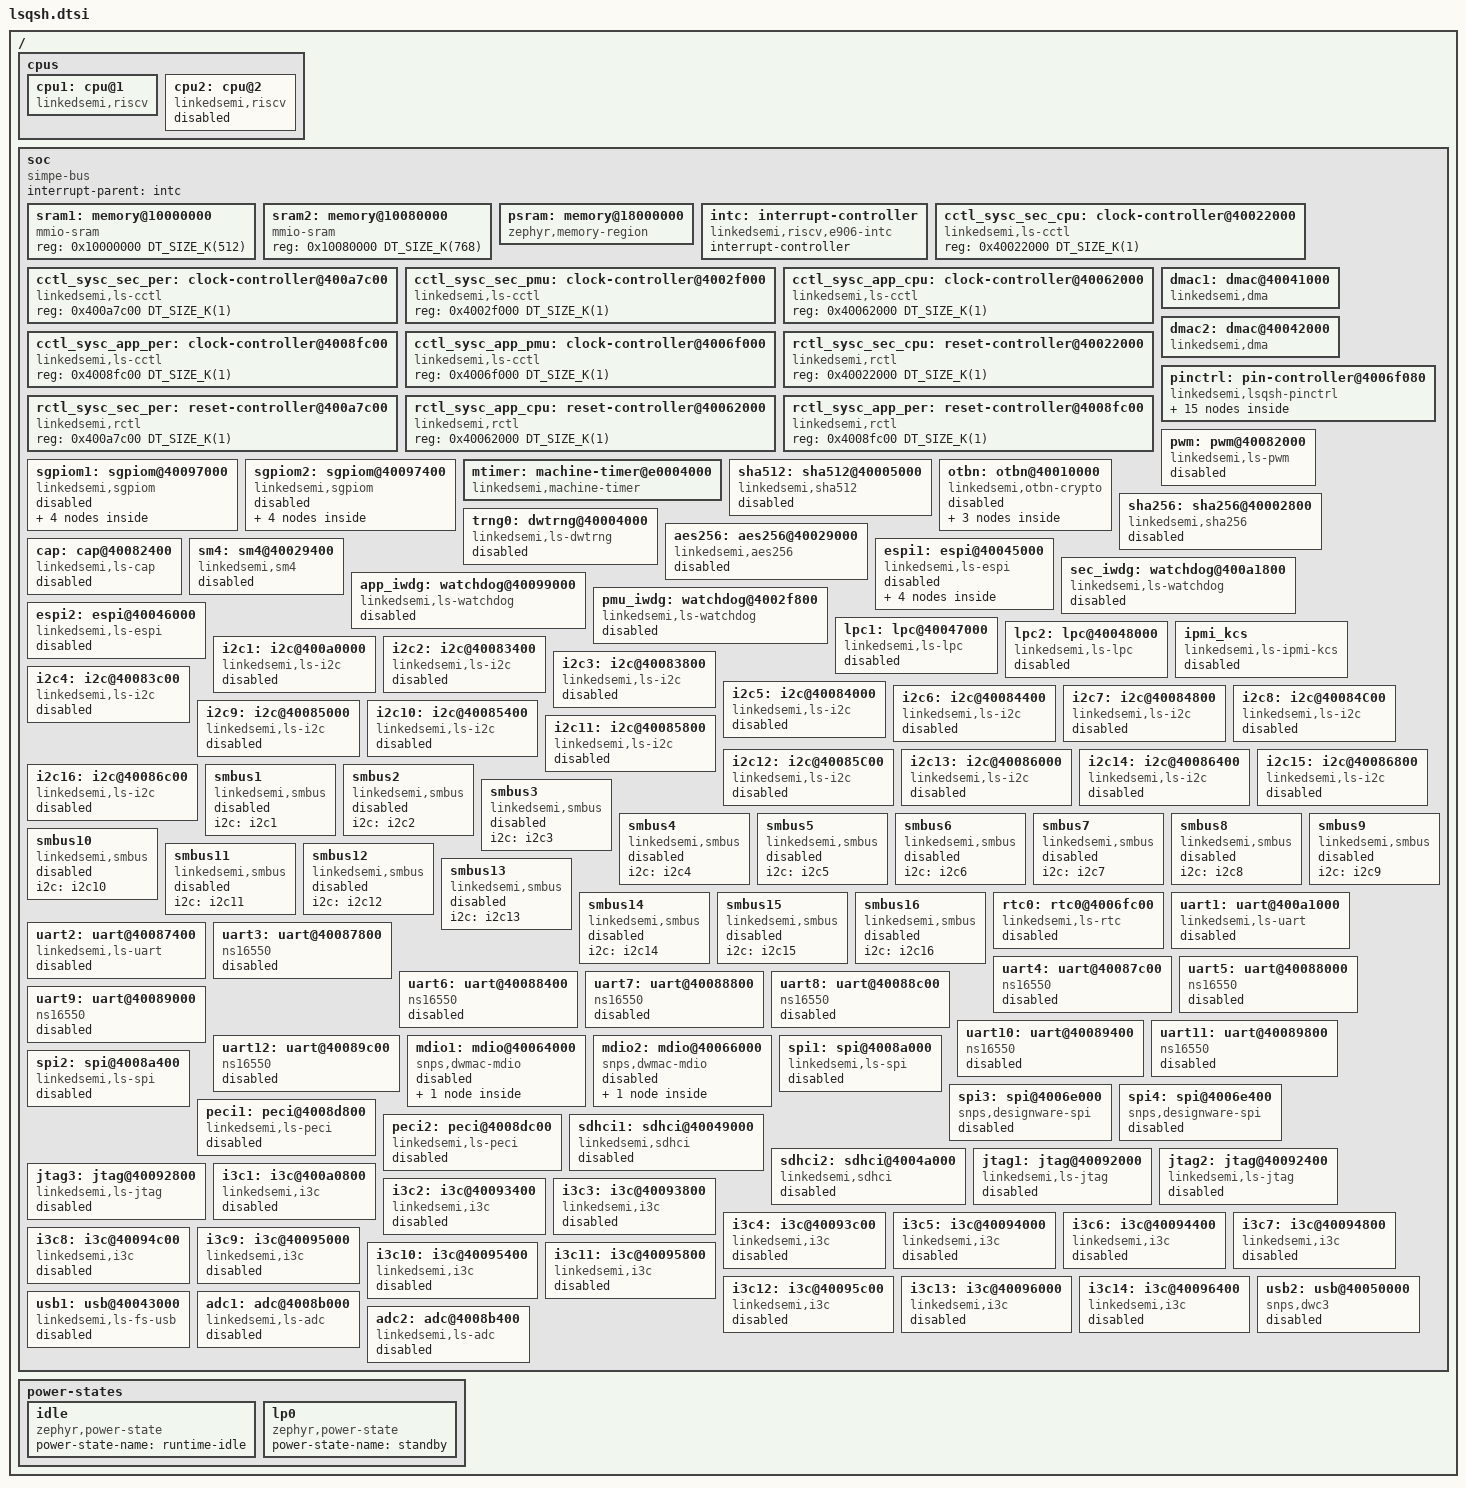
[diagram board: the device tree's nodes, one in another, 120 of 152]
#include <zephyr/dt-bindings/pinctrl/lsqsh-pinctrl.h>
#include <zephyr/dt-bindings/clock/lsqsh_clock.h>
#include <zephyr/dt-bindings/reset/lsqsh_reset.h>
#include <zephyr/dt-bindings/gpio/gpio.h>
#include <mem.h>
#include <freq.h>
#include <dmac_config.h>

#include <zephyr/dt-bindings/memory-attr/memory-attr.h>
#include <zephyr/dt-bindings/memory-attr/memory-attr-riscv.h>
#include <qsh.h>

#define CPU_CLOCK      DT_FREQ_M(600)
#define PBUS0123_CLOCK DT_FREQ_M(300)
#define PBUS4_CLOCK    DT_FREQ_M(75)
#define SDHCI_CLOCK    DT_FREQ_M(200)

/ {
    #address-cells = <1>;
    #size-cells = <1>;

    cpus {
        #address-cells = <1>;
        #size-cells = <0>;
        cpu1: cpu@1 {
            device_type = "cpu";
            compatible = "linkedsemi,riscv";
            riscv,isa = "rv32imafcxp";
            reg = <1>;
            clock-frequency = <CPU_CLOCK>;
            cpu-power-states = <&idle &lp0>;
        };
        cpu2: cpu@2 {
            device_type = "cpu";
            compatible = "linkedsemi,riscv";
            riscv,isa = "rv32imafcxp";
            reg = <2>;
            clock-frequency = <CPU_CLOCK>;
            cpu-power-states = <&idle &lp0>;
            status = "disabled";
        };
    };

    soc {
        compatible = "simpe-bus";
        #address-cells = <1>;
        #size-cells = <1>;
        interrupt-parent = <&intc>;

        sram1: memory@10000000 {
            compatible = "mmio-sram";
            reg = <0x10000000 DT_SIZE_K(512)>;
        };

        sram2: memory@10080000{
            compatible = "mmio-sram";
            reg = <0x10080000 DT_SIZE_K(768)>;
        };

/*
        share_memory0: memory@1013f000{
            compatible = "mmio-sram";
            reg = <0x1013f000 0x1000>;
        };
*/
        psram: memory@18000000 {
            compatible = "zephyr,memory-region", "mmio-sram";
            reg = <0x18000000 DT_SIZE_M(8)>;
            zephyr,memory-region = "PSRAM";
            status = "okay";
        };

        intc: interrupt-controller {
            compatible = "linkedsemi,riscv,e906-intc";
            #address-cells = <0>;
            #interrupt-cells = <2>;
            interrupt-controller;
        };

        cctl_sysc_sec_cpu: clock-controller@40022000 {
            compatible = "linkedsemi,ls-cctl";
            reg = <0x40022000 DT_SIZE_K(1)>;
            #clock-cells = <3>;
            status = "okay";
        };

        cctl_sysc_sec_per: clock-controller@400a7c00 {
            compatible = "linkedsemi,ls-cctl";
            reg = <0x400a7c00 DT_SIZE_K(1)>;
            #clock-cells = <3>;
            status = "okay";
        };

        cctl_sysc_sec_pmu: clock-controller@4002f000 {
            compatible = "linkedsemi,ls-cctl";
            reg = <0x4002f000 DT_SIZE_K(1)>;
            #clock-cells = <3>;
            status = "okay";
        };

        cctl_sysc_app_cpu: clock-controller@40062000 {
            compatible = "linkedsemi,ls-cctl";
            reg = <0x40062000 DT_SIZE_K(1)>;
            #clock-cells = <3>;
            status = "okay";
        };

        cctl_sysc_app_per: clock-controller@4008fc00 {
            compatible = "linkedsemi,ls-cctl";
            reg = <0x4008fc00 DT_SIZE_K(1)>;
            #clock-cells = <3>;
            status = "okay";
        };

        cctl_sysc_app_pmu: clock-controller@4006f000 {
            compatible = "linkedsemi,ls-cctl";
            reg = <0x4006f000 DT_SIZE_K(1)>;
            #clock-cells = <3>;
            status = "okay";
        };

        rctl_sysc_sec_cpu: reset-controller@40022000 {
            compatible = "linkedsemi,rctl";
            reg = <0x40022000 DT_SIZE_K(1)>;
            #reset-cells = <1>;
            status = "okay";
        };

        rctl_sysc_sec_per: reset-controller@400a7c00 {
            compatible = "linkedsemi,rctl";
            reg = <0x400a7c00 DT_SIZE_K(1)>;
            #reset-cells = <1>;
            status = "okay";
        };

        rctl_sysc_app_cpu: reset-controller@40062000 {
            compatible = "linkedsemi,rctl";
            reg = <0x40062000 DT_SIZE_K(1)>;
            #reset-cells = <1>;
            status = "okay";
        };

        rctl_sysc_app_per: reset-controller@4008fc00 {
            compatible = "linkedsemi,rctl";
            reg = <0x4008fc00 DT_SIZE_K(1)>;
            #reset-cells = <1>;
            status = "okay";
        };

        dmac1: dmac@40041000 {
            compatible = "linkedsemi,dma", "snps,designware-dma-2.20a";
            reg = <0x40041000 0x1000>;
            #dma-cells = <2>;
            interrupts = <DMAC1_IRQN 3>;
            clocks = <DMAC1_CLOCK>;
            resets = <DMAC1_RESET>;
            interrupt-parent = <&intc>;
            dma-channels = <8>;
            dma-buf-addr-alignment = <4>;
            status = "okay";
        };

        dmac2: dmac@40042000 {
            compatible = "linkedsemi,dma", "snps,designware-dma-2.20a";
            reg = <0x40042000 0x1000>;
            #dma-cells = <2>;
            interrupts = <DMAC2_IRQN 3>;
            clocks = <DMAC2_CLOCK>;
            resets = <DMAC2_RESET>;
            interrupt-parent = <&intc>;
            dma-channels = <8>;
            dma-buf-addr-alignment = <4>;
            status = "okay";
        };

        pinctrl: pin-controller@4006f080 {
            compatible = "linkedsemi,lsqsh-pinctrl";
            reg = <0x4006f080 0x200>;
            interrupts = <PMU_EXT_SEC_IRQN 3>, <PMU_EXT_APP_IRQN 3>;
            interrupt-names = "cpu1", "cpu2";
            #address-cells = <1>;
            #size-cells = <1>;

            gpioa: gpio@4006f180 {
                compatible = "linkedsemi,lsqsh-gpio";
                gpio-controller;
                #gpio-cells = <2>;
                reg = <0x4006f180 0x20>, <0x4006f360 0x8>;
                reg-names = "io_cfg", "io_val";
                status = "disabled";
            };

            gpiob: gpio@4006f1a0 {
                compatible = "linkedsemi,lsqsh-gpio";
                gpio-controller;
                #gpio-cells = <2>;
                reg = <0x4006f1a0 0x20>, <0x4006f368 0x8>;
                reg-names = "io_cfg", "io_val";
                status = "disabled";
            };

            gpioc: gpio@4006f1c0 {
                compatible = "linkedsemi,lsqsh-gpio";
                gpio-controller;
                #gpio-cells = <2>;
                reg = <0x4006f1c0 0x20>, <0x4006f370 0x8>;
                reg-names = "io_cfg", "io_val";
                status = "disabled";
            };

            gpiod: gpio@4006f1e0 {
                compatible = "linkedsemi,lsqsh-gpio";
                gpio-controller;
                #gpio-cells = <2>;
                reg = <0x4006f1e0 0x20>, <0x4006f378 0x8>;
                reg-names = "io_cfg", "io_val";
                status = "disabled";
            };

            gpioe: gpio@4006f200 {
                compatible = "linkedsemi,lsqsh-gpio";
                gpio-controller;
                #gpio-cells = <2>;
                reg = <0x4006f200 0x20>, <0x4006f380 0x8>;
                reg-names = "io_cfg", "io_val";
                status = "disabled";
            };

            gpiof: gpio@4006f220 {
                compatible = "linkedsemi,lsqsh-gpio";
                gpio-controller;
                #gpio-cells = <2>;
                reg = <0x4006f220 0x20>, <0x4006f388 0x8>;
                reg-names = "io_cfg", "io_val";
                status = "disabled";
            };

            gpiog: gpio@4006f240 {
                compatible = "linkedsemi,lsqsh-gpio";
                gpio-controller;
                #gpio-cells = <2>;
                reg = <0x4006f240 0x20>, <0x4006f390 0x8>;
                reg-names = "io_cfg", "io_val";
                status = "disabled";
            };

            gpioh: gpio@4006f260 {
                compatible = "linkedsemi,lsqsh-gpio";
                gpio-controller;
                #gpio-cells = <2>;
                reg = <0x4006f260 0x20>, <0x4006f398 0x8>;
                reg-names = "io_cfg", "io_val";
                status = "disabled";
            };

            gpioi: gpio@4006f280 {
                compatible = "linkedsemi,lsqsh-gpio";
                gpio-controller;
                #gpio-cells = <2>;
                reg = <0x4006f280 0x20>, <0x4006f3a0 0x8>;
                reg-names = "io_cfg", "io_val";
                status = "disabled";
            };

            gpioj: gpio@4006f2a0 {
                compatible = "linkedsemi,lsqsh-gpio";
                gpio-controller;
                #gpio-cells = <2>;
                reg = <0x4006f2a0 0x20>, <0x4006f3a8 0x8>;
                reg-names = "io_cfg", "io_val";
                status = "disabled";
            };

            gpiok: gpio@4006f2c0 {
                compatible = "linkedsemi,lsqsh-gpio";
                gpio-controller;
                #gpio-cells = <2>;
                reg = <0x4006f2c0 0x20>, <0x4006f3b0 0x8>;
                reg-names = "io_cfg", "io_val";
                status = "disabled";
            };

            gpiom: gpio@4006f2e0 {
                compatible = "linkedsemi,lsqsh-gpio";
                gpio-controller;
                #gpio-cells = <2>;
                reg = <0x4006f2e0 0x20>, <0x4006f3b8 0x8>;
                reg-names = "io_cfg", "io_val";
                status = "disabled";
            };

            gpion: gpio@4006f300 {
                compatible = "linkedsemi,lsqsh-gpio";
                gpio-controller;
                #gpio-cells = <2>;
                reg = <0x4006f300 0x20>, <0x4006f3c0 0x8>;
                reg-names = "io_cfg", "io_val";
                status = "disabled";
            };

            gpioq: gpio@4006f320 {
                compatible = "linkedsemi,lsqsh-gpio";
                gpio-controller;
                #gpio-cells = <2>;
                reg = <0x4006f320 0x20>, <0x4006f3c8 0x8>;
                reg-names = "io_cfg", "io_val";
                status = "disabled";
            };

            gpiot: gpio@4006f340 {
                compatible = "linkedsemi,lsqsh-gpio";
                gpio-controller;
                #gpio-cells = <2>;
                reg = <0x4006f340 0x20>, <0x4006f3d0 0x8>;
                reg-names = "io_cfg", "io_val";
                status = "disabled";
            };
        };

        pwm:pwm@40082000 {
            compatible = "linkedsemi,ls-pwm";
            reg = <0x40082000 0x100>;
            clocks = <PWM_CLOCK>;
            resets = <PWM_RESET>;
            clock-frequency = <PBUS4_CLOCK>;
            #pwm-cells = <3>;
            status = "disabled";
        };

        sgpiom1: sgpiom@40097000 {
            compatible = "linkedsemi,sgpiom";
            reg = <0x40097000 0x400>;
            interrupts = <151 3>;
            interrupts = <CALC_SM4_IRQN 3>;
            clocks = <SGPIO1_MST_CLOCK>;
            resets = <SGPIO1_MST_RESET>;
            ngpios = <256>;
            linkedsemi,bus-freq = <1000000>;
            status = "disabled";

            sgpiom_a_d: sgpiom_a_d {
                #gpio-cells = <2>;
                gpio-controller;
                ngpios = <32>;
                #address-cells = <0>;
                interrupt-controller;
                #interrupt-cells = <2>;
                pin-offset = <0>;
                status = "disabled";
            };

            sgpiom_e_h: sgpiom_e_h {
                #gpio-cells = <2>;
                gpio-controller;
                ngpios = <32>;
                #address-cells = <0>;
                interrupt-controller;
                #interrupt-cells = <2>;
                pin-offset = <32>;
                status = "disabled";
            };

            sgpiom_i_l: sgpiom_i_l {
                #gpio-cells = <2>;
                gpio-controller;
                ngpios = <32>;
                #address-cells = <0>;
                interrupt-controller;
                #interrupt-cells = <2>;
                pin-offset = <64>;
                status = "disabled";
            };

            sgpiom_m_p: sgpiom_m_p {
                #gpio-cells = <2>;
                gpio-controller;
                ngpios = <32>;
                #address-cells = <0>;
                interrupt-controller;
                #interrupt-cells = <2>;
                pin-offset = <96>;
                status = "disabled";
            };
        };

        sgpiom2: sgpiom@40097400 {
            compatible = "linkedsemi,sgpiom";
            reg = <0x40097400 0x400>;
            interrupts = <152 3>;
            clocks = <SGPIO2_MST_CLOCK>;
            resets = <SGPIO2_MST_RESET>;
            ngpios = <256>;
            linkedsemi,bus-freq = <1000000>;
            status = "disabled";

            sgpiom2_a_d: sgpiom2_a_d {
                #gpio-cells = <2>;
                gpio-controller;
                ngpios = <32>;
                #address-cells = <0>;
                interrupt-controller;
                #interrupt-cells = <2>;
                pin-offset = <0>;
                status = "disabled";
            };

            sgpiom2_e_h: sgpiom2_e_h {
                #gpio-cells = <2>;
                gpio-controller;
                ngpios = <32>;
                #address-cells = <0>;
                interrupt-controller;
                #interrupt-cells = <2>;
                pin-offset = <32>;
                status = "disabled";
            };

            sgpiom2_i_l: sgpiom2_i_l {
                #gpio-cells = <2>;
                gpio-controller;
                ngpios = <32>;
                #address-cells = <0>;
                interrupt-controller;
                #interrupt-cells = <2>;
                pin-offset = <64>;
                status = "disabled";
            };

            sgpiom2_m_p: sgpiom2_m_p {
                #gpio-cells = <2>;
                gpio-controller;
                ngpios = <32>;
                #address-cells = <0>;
                interrupt-controller;
                #interrupt-cells = <2>;
                pin-offset = <96>;
                status = "disabled";
            };
        };

        mtimer: machine-timer@e0004000 {
            compatible = "linkedsemi,machine-timer";
            reg = <0xe0004000 0x8000>;
            interrupts = <RV_TIME_IRQN 0>;
        };

        sha512:sha512@40005000 {
            compatible = "linkedsemi,sha512";
            reg = <0x40005000 0x400>;
            interrupts = <SHA512_IRQN 3>;
            clocks = <SHA512_CLOCK>;
            resets = <SHA512_RESET>;
            status = "disabled";
        };

        otbn:otbn@40010000 {
            compatible = "linkedsemi,otbn-crypto";
            reg = <0x40010000 0x400>;
            interrupts = <OBTN_IRQN 3>;
            clocks = <OTBN_CLOCK>;
            status = "disabled";
            sm2: otbn-sm2 {
                compatible = "linkedsemi,otbn-sm2";
                otbn-parent = <&otbn>;
                status = "disabled";
            };
            ecc_p256: otbn-p256 {
                compatible = "linkedsemi,otbn-ecc-p256";
                otbn-parent = <&otbn>;
                status = "disabled";
            };
            ecc_p384: otbn-p384 {
                compatible = "linkedsemi,otbn-ecc-p384";
                otbn-parent = <&otbn>;
                status = "disabled";
            };
        };

        sha256:sha256@40002800 {
            compatible = "linkedsemi,sha256";
            reg = <0x40002800 0x400>;
            interrupts = <CALC_SHA256_IRQN 3>;
            clocks = <CALC_SHA_CLOCK>;
            resets = <CALC_SHA_RESET>;
            status = "disabled";
        };

        trng0: dwtrng@40004000 {
            compatible = "linkedsemi,ls-dwtrng";
            reg = <0x40004000 0x400>;
            status = "disabled";
            clocks = <NIST_TRNG_CLOCK>;
            resets = <NIST_TRNG_RESET>;
            interrupts = <NIST_TRNG_IRQN 3>;
        };


        aes256: aes256@40029000 {
            compatible = "linkedsemi,aes256";
            reg = <0x40029000 0x400>;
            interrupts = <CALC_AES256_IRQN 3>;
            clocks = <CRYPT_CLOCK>;
            resets = <CRYPT_RESET>;
            status = "disabled";
        };

        cap:cap@40082400 {
            compatible = "linkedsemi,ls-cap";
            reg = <0x40082400 0x400>;
            status = "disabled";
            interrupts = <CAP_IRQN 3>;
            clocks = <CAP_CLOCK>;
            clock-frequency = <PBUS4_CLOCK>;
        };

        sm4:sm4@40029400 {
            compatible = "linkedsemi,sm4";
            reg = <0x40029400 0x400>;
            interrupts = <CALC_SM4_IRQN 3>;
            clocks = <CALC_SM4_CLOCK>;
            resets = <CALC_SM4_RESET>;
            status = "disabled";
        };

        espi1: espi@40045000 {
            compatible = "linkedsemi,ls-espi";
            reg = <0x40045000 0x1000>;
            interrupts = <ESPI1_IRQN 3>;
            clocks = <ESPI1_CLOCK>;
            resets = <ESPI1_RESET>;
            #address-cells = <1>;
            #size-cells = <1>;
            status = "disabled";

            vuart1: vuart1@40087800 {
                compatible = "linkedsemi,ls-host-vuart";
                reg = <0x40087800 0x400>;
                interrupts = <UART3_IRQN 3>;
                clocks = <UART3_CLOCK>;
                resets = <UART3_RESET>;
                port = <0x3f8>;
                up-irq = <0x4 0>;
                target = <&vuart_v0>;
                status = "disabled";
            };

            sio1: sio1 {
                compatible = "linkedsemi,ls-sio";
                port = <0x2e>;
                status = "disabled";
            };

            mmbi1: mmbi1 {
                compatible = "linkedsemi,ls-mmbi";
                host-addr = <0xf6810000>;
                size-order = <0>;
                status = "disabled";
            };

            vuart_v0: vuart@0 {
                compatible = "linkedsemi,vuart";
                status = "disabled";
                reg = <0x0 0x10>;
            };

        };
        
  
        sec_iwdg: watchdog@400a1800 {
          compatible = "linkedsemi,ls-watchdog";
          reg = <0x400a1800 0x400>;
          interrupts = <IWDT1_IRQN  4>;
          status = "disabled";
          clocks = <IWDT1_CLOCK>;
          resets = <IWDT1_RESET>;
          clock-frequency = <32768>;
        };
        app_iwdg: watchdog@40099000{
          compatible = "linkedsemi,ls-watchdog";
          reg = <0x40099000 0x400>;
          interrupts = <IWDT2_IRQN 4>;
          status = "disabled";
          clocks = <IWDT2_CLOCK>;
          resets = <IWDT2_RESET>;
          clock-frequency = <32768>;
        };
        pmu_iwdg: watchdog@4002f800{
          compatible = "linkedsemi,ls-watchdog";
          reg = <0x4002f800 0x400>;
          interrupts = <PMU_WDT_IRQN 4>;
          status = "disabled";
          clocks = <WDT_CLOCK>;
          clock-frequency = <32768>;
        };

        espi2: espi@40046000 {
            compatible = "linkedsemi,ls-espi";
            reg = <0x40046000 0x1000>;
            interrupts = <ESPI2_IRQN 3>;
            clocks = <ESPI2_CLOCK>;
            resets = <ESPI2_RESET>;
            status = "disabled";
        };

        lpc1: lpc@40047000 {
            compatible = "linkedsemi,ls-lpc";
            reg = <0x40047000 0x1000>;
            interrupts = <LPC1_IRQN 3>;
            clocks = <LPC1_CLOCK>;
            resets = <LPC1_RESET>;
            status = "disabled";
        };

        lpc2: lpc@40048000 {
            compatible = "linkedsemi,ls-lpc";
            reg = <0x40048000 0x1000>;
            interrupts = <LPC2_IRQN 3>;
            clocks = <LPC2_CLOCK>;
            resets = <LPC2_RESET>;
            status = "disabled";
        };

        ipmi_kcs: ipmi_kcs {
            compatible = "linkedsemi,ls-ipmi-kcs";
            status = "disabled";
        };

        i2c1: i2c@400a0000 {
            compatible = "linkedsemi,ls-i2c";
            reg = <0x400a0000 0x400>;
            #address-cells = <1>;
            #size-cells = <0>;
            interrupts = <I2C1_IRQN 3>;
            clocks = <I2C1_CLOCK>;
            resets = <I2C1_RESET>;
            clock-frequency = <PBUS4_CLOCK>;
            status = "disabled";
        };

        i2c2: i2c@40083400 {
            compatible = "linkedsemi,ls-i2c";
            reg = <0x40083400 0x400>;
            #address-cells = <1>;
            #size-cells = <0>;
            interrupts = <I2C2_IRQN 3>;
            clocks = <I2C2_CLOCK>;
            resets = <I2C2_RESET>;
            clock-frequency = <PBUS4_CLOCK>;
            status = "disabled";
        };

        i2c3: i2c@40083800 {
            compatible = "linkedsemi,ls-i2c";
            reg = <0x40083800 0x400>;
            #address-cells = <1>;
            #size-cells = <0>;
            interrupts = <I2C3_IRQN 3>;
            clocks = <I2C3_CLOCK>;
            resets = <I2C3_RESET>;
            clock-frequency = <PBUS4_CLOCK>;
            status = "disabled";
        };

        i2c4: i2c@40083c00 {
            compatible = "linkedsemi,ls-i2c";
            reg = <0x40083c00 0x400>;
            #address-cells = <1>;
            #size-cells = <0>;
            interrupts = <I2C4_IRQN 3>;
            clocks = <I2C4_CLOCK>;
            resets = <I2C4_RESET>;
            clock-frequency = <PBUS4_CLOCK>;
            status = "disabled";
        };

        i2c5: i2c@40084000 {
            compatible = "linkedsemi,ls-i2c";
            reg = <0x40084000 0x400>;
            #address-cells = <1>;
            #size-cells = <0>;
            interrupts = <I2C5_IRQN 3>;
            clocks = <I2C5_CLOCK>;
            resets = <I2C5_RESET>;
            clock-frequency = <PBUS4_CLOCK>;
            status = "disabled";
        };

        i2c6: i2c@40084400 {
            compatible = "linkedsemi,ls-i2c";
            reg = <0x40084400 0x400>;
            #address-cells = <1>;
            #size-cells = <0>;
            interrupts = <I2C6_IRQN 3>;
            clocks = <I2C6_CLOCK>;
            resets = <I2C6_RESET>;
            clock-frequency = <PBUS4_CLOCK>;
            status = "disabled";
        };

        i2c7: i2c@40084800 {
            compatible = "linkedsemi,ls-i2c";
            reg = <0x40084800 0x400>;
            #address-cells = <1>;
            #size-cells = <0>;
            interrupts = <I2C7_IRQN 3>;
            clocks = <I2C7_CLOCK>;
            resets = <I2C7_RESET>;
            clock-frequency = <PBUS4_CLOCK>;
            status = "disabled";
        };

        i2c8: i2c@40084C00 {
            compatible = "linkedsemi,ls-i2c";
            reg = <0x40084C00 0x400>;
            #address-cells = <1>;
            #size-cells = <0>;
            interrupts = <I2C8_IRQN 3>;
            clocks = <I2C8_CLOCK>;
            resets = <I2C8_RESET>;
            clock-frequency = <PBUS4_CLOCK>;
            status = "disabled";
        };

        i2c9: i2c@40085000 {
            compatible = "linkedsemi,ls-i2c";
            reg = <0x40085000 0x400>;
            #address-cells = <1>;
            #size-cells = <0>;
            interrupts = <I2C9_IRQN 3>;
            clocks = <I2C9_CLOCK>;
            resets = <I2C9_RESET>;
            clock-frequency = <PBUS4_CLOCK>;
            status = "disabled";
        };

        i2c10: i2c@40085400 {
            compatible = "linkedsemi,ls-i2c";
            reg = <0x40085400 0x400>;
            #address-cells = <1>;
            #size-cells = <0>;
            interrupts = <I2C10_IRQN 3>;
            clocks = <I2C10_CLOCK>;
            resets = <I2C10_RESET>;
            clock-frequency = <PBUS4_CLOCK>;
            status = "disabled";
        };

        i2c11: i2c@40085800 {
            compatible = "linkedsemi,ls-i2c";
            reg = <0x40085800 0x400>;
            #address-cells = <1>;
            #size-cells = <0>;
            interrupts = <I2C11_IRQN 3>;
            clocks = <I2C11_CLOCK>;
            resets = <I2C11_RESET>;
            clock-frequency = <PBUS4_CLOCK>;
            status = "disabled";
        };

        i2c12: i2c@40085C00 {
            compatible = "linkedsemi,ls-i2c";
            reg = <0x40085C00 0x400>;
            #address-cells = <1>;
            #size-cells = <0>;
            interrupts = <I2C12_IRQN 3>;
            clocks = <I2C12_CLOCK>;
            resets = <I2C12_RESET>;
            clock-frequency = <PBUS4_CLOCK>;
            status = "disabled";
        };

        i2c13: i2c@40086000 {
            compatible = "linkedsemi,ls-i2c";
            reg = <0x40086000 0x400>;
            #address-cells = <1>;
            #size-cells = <0>;
            interrupts = <I2C13_IRQN 3>;
            clocks = <I2C13_CLOCK>;
            resets = <I2C13_RESET>;
            clock-frequency = <PBUS4_CLOCK>;
            status = "disabled";
        };

        i2c14: i2c@40086400 {
            compatible = "linkedsemi,ls-i2c";
            reg = <0x40086400 0x400>;
            #address-cells = <1>;
            #size-cells = <0>;
            interrupts = <I2C14_IRQN 3>;
            clocks = <I2C14_CLOCK>;
            resets = <I2C14_RESET>;
            clock-frequency = <PBUS4_CLOCK>;
            status = "disabled";
        };

        i2c15: i2c@40086800 {
            compatible = "linkedsemi,ls-i2c";
            reg = <0x40086800 0x400>;
            #address-cells = <1>;
            #size-cells = <0>;
            interrupts = <I2C15_IRQN 3>;
            clocks = <I2C15_CLOCK>;
            resets = <I2C15_RESET>;
            clock-frequency = <PBUS4_CLOCK>;
            status = "disabled";
        };

        i2c16: i2c@40086c00 {
            compatible = "linkedsemi,ls-i2c";
            reg = <0x40086c00 0x400>;
            #address-cells = <1>;
            #size-cells = <0>;
            interrupts = <I2C16_IRQN 3>;
            clocks = <I2C16_CLOCK>;
            resets = <I2C16_RESET>;
            clock-frequency = <PBUS4_CLOCK>;
            status = "disabled";
        };

        smbus1: smbus1 {
            compatible = "linkedsemi,smbus";
            #address-cells = <1>;
            #size-cells = <0>;
            i2c = <&i2c1>;
            status = "disabled";
        };

        smbus2: smbus2 {
            compatible = "linkedsemi,smbus";
            #address-cells = <1>;
            #size-cells = <0>;
            i2c = <&i2c2>;
            status = "disabled";
        };

        smbus3: smbus3 {
            compatible = "linkedsemi,smbus";
            #address-cells = <1>;
            #size-cells = <0>;
            i2c = <&i2c3>;
            status = "disabled";
        };

        smbus4: smbus4 {
            compatible = "linkedsemi,smbus";
            #address-cells = <1>;
            #size-cells = <0>;
            i2c = <&i2c4>;
            status = "disabled";
        };

        smbus5: smbus5 {
            compatible = "linkedsemi,smbus";
            #address-cells = <1>;
            #size-cells = <0>;
            i2c = <&i2c5>;
            status = "disabled";
        };

        smbus6: smbus6 {
            compatible = "linkedsemi,smbus";
            #address-cells = <1>;
            #size-cells = <0>;
            i2c = <&i2c6>;
            status = "disabled";
        };

        smbus7: smbus7 {
            compatible = "linkedsemi,smbus";
            #address-cells = <1>;
            #size-cells = <0>;
            i2c = <&i2c7>;
            status = "disabled";
        };

        smbus8: smbus8 {
            compatible = "linkedsemi,smbus";
            #address-cells = <1>;
            #size-cells = <0>;
            i2c = <&i2c8>;
            status = "disabled";
        };

        smbus9: smbus9 {
            compatible = "linkedsemi,smbus";
            #address-cells = <1>;
            #size-cells = <0>;
            i2c = <&i2c9>;
            status = "disabled";
        };

        smbus10: smbus10 {
            compatible = "linkedsemi,smbus";
            #address-cells = <1>;
            #size-cells = <0>;
            i2c = <&i2c10>;
            status = "disabled";
        };

        smbus11: smbus11 {
            compatible = "linkedsemi,smbus";
            #address-cells = <1>;
            #size-cells = <0>;
            i2c = <&i2c11>;
            status = "disabled";
        };

        smbus12: smbus12 {
            compatible = "linkedsemi,smbus";
            #address-cells = <1>;
            #size-cells = <0>;
            i2c = <&i2c12>;
            status = "disabled";
        };

        smbus13: smbus13 {
            compatible = "linkedsemi,smbus";
            #address-cells = <1>;
            #size-cells = <0>;
            i2c = <&i2c13>;
            status = "disabled";
        };

        smbus14: smbus14 {
            compatible = "linkedsemi,smbus";
            #address-cells = <1>;
            #size-cells = <0>;
            i2c = <&i2c14>;
            status = "disabled";
        };

        smbus15: smbus15 {
            compatible = "linkedsemi,smbus";
            #address-cells = <1>;
            #size-cells = <0>;
            i2c = <&i2c15>;
            status = "disabled";
        };

        smbus16: smbus16 {
            compatible = "linkedsemi,smbus";
            #address-cells = <1>;
            #size-cells = <0>;
            i2c = <&i2c16>;
            status = "disabled";
        };

        rtc0: rtc0@4006fc00{
            compatible = "linkedsemi,ls-rtc";
            reg = <0x4006fc00 0x400>;
            interrupts = <PMU_RTC_IRQN 3>;
            clock-frequency = <32768>;
            clocks = <RTC_CLOCK>;
            cyc-1hz = <32768>;     // 实际频率
            calib-cyc = <0>;          // 校准补偿周期数，单位是时钟周期
            calib-enable;             // 若存在此属性，则表示启用校准
            status = "disabled";
        };

        uart1: uart@400a1000 {
            compatible = "linkedsemi,ls-uart";
            reg = <0x400a1000 0x400>;
            interrupts = <UART1_IRQN 3>;
            clock-frequency = <PBUS4_CLOCK>;
            clocks = <UART1_CLOCK>;
            resets = <UART1_RESET>;
            current-speed = <115200>;
            status = "disabled";
        };

        uart2: uart@40087400 {
            compatible = "linkedsemi,ls-uart";
            reg = <0x40087400 0x400>;
            interrupts = <UART2_IRQN 3>;
            clock-frequency = <PBUS4_CLOCK>;
            clocks = <UART2_CLOCK>;
            resets = <UART2_RESET>;
            current-speed = <115200>;
            status = "disabled";
        };

        uart3: uart@40087800 {
            compatible = "ns16550";
            reg = <0x40087800 0x400>;
            clock-frequency = <PBUS4_CLOCK>;
            interrupts = <UART3_IRQN 3>;
            clocks = <UART3_CLOCK>;
            resets = <UART3_RESET>;
            reg-shift = <2>;
            current-speed = <115200>;
            status = "disabled";
        };

        uart4: uart@40087c00 {
            compatible = "ns16550";
            reg = <0x40087c00 0x400>;
            clock-frequency = <PBUS4_CLOCK>;
            interrupts = <UART4_IRQN 3>;
            clocks = <UART4_CLOCK>;
            resets = <UART4_RESET>;
            reg-shift = <2>;
            current-speed = <115200>;
            status = "disabled";
        };

        uart5: uart@40088000 {
            compatible = "ns16550";
            reg = <0x40088000 0x400>;
            clock-frequency = <PBUS4_CLOCK>;
            interrupts = <UART5_IRQN 3>;
            clocks = <UART5_CLOCK>;
            resets = <UART5_RESET>;
            reg-shift = <2>;
            current-speed = <115200>;
            status = "disabled";
        };

        uart6: uart@40088400 {
            compatible = "ns16550";
            reg = <0x40088400 0x400>;
            clock-frequency = <PBUS4_CLOCK>;
            interrupts = <UART6_IRQN 3>;
            clocks = <UART6_CLOCK>;
            resets = <UART6_RESET>;
            reg-shift = <2>;
            current-speed = <115200>;
            status = "disabled";
        };

        uart7: uart@40088800 {
            compatible = "ns16550";
            reg = <0x40088800 0x400>;
            clock-frequency = <PBUS4_CLOCK>;
            interrupts = <UART7_IRQN 3>;
            clocks = <UART7_CLOCK>;
            resets = <UART7_RESET>;
            reg-shift = <2>;
            current-speed = <115200>;
            status = "disabled";
        };

        uart8: uart@40088c00 {
            compatible = "ns16550";
            reg = <0x40088c00 0x400>;
            clock-frequency = <PBUS4_CLOCK>;
            interrupts = <UART8_IRQN 3>;
            clocks = <UART8_CLOCK>;
            resets = <UART8_RESET>;
            reg-shift = <2>;
            current-speed = <115200>;
            status = "disabled";
        };

        uart9: uart@40089000 {
            compatible = "ns16550";
            reg = <0x40089000 0x400>;
            clock-frequency = <PBUS4_CLOCK>;
            interrupts = <UART9_IRQN 3>;
            clocks = <UART9_CLOCK>;
            resets = <UART9_RESET>;
            reg-shift = <2>;
            current-speed = <115200>;
            status = "disabled";
        };

        uart10: uart@40089400 {
            compatible = "ns16550";
            reg = <0x40089400 0x400>;
            clock-frequency = <PBUS4_CLOCK>;
            interrupts = <UART10_IRQN 3>;
            clocks = <UART10_CLOCK>;
            resets = <UART10_RESET>;
            reg-shift = <2>;
            current-speed = <115200>;
            status = "disabled";
        };

        uart11: uart@40089800 {
            compatible = "ns16550";
            reg = <0x40089800 0x400>;
            clock-frequency = <PBUS4_CLOCK>;
            interrupts = <UART11_IRQN 3>;
            clocks = <UART11_CLOCK>;
            resets = <UART11_RESET>;
            reg-shift = <2>;
            current-speed = <115200>;
            status = "disabled";
        };

        uart12: uart@40089c00 {
            compatible = "ns16550";
            reg = <0x40089c00 0x400>;
            clock-frequency = <PBUS4_CLOCK>;
            interrupts = <UART12_IRQN 3>;
            clocks = <UART12_CLOCK>;
            resets = <UART12_RESET>;
            reg-shift = <2>;
            current-speed = <115200>;
            status = "disabled";
        };

        mdio1: mdio@40064000 {
            compatible = "snps,dwmac-mdio";
            reg = <0x40064000 0x2000>;
            clock-frequency = <PBUS0123_CLOCK>;
            clocks = <ETH1_CLOCK>;
            resets = <ETH1_RESET>;
            #address-cells = <1>;
            #size-cells = <0>;
            status = "disabled";

            eth1: ethernet@40064000 {
                compatible = "linkedsemi,ethernet", "snps,designware-ethernet";
                reg = <0x40064000 0x2000>;
                interrupts = <ETH1_IRQN 3>;
                clock-frequency = <PBUS0123_CLOCK>;
                clocks = <ETH1_CLOCK>;
                resets = <ETH1_RESET>;
                status = "disabled";
            };
        };

        mdio2: mdio@40066000 {
            compatible = "snps,dwmac-mdio";
            reg = <0x40066000 0x2000>;
            clock-frequency = <PBUS0123_CLOCK>;
            clocks = <ETH2_CLOCK>;
            resets = <ETH2_RESET>;
            #address-cells = <1>;
            #size-cells = <0>;
            status = "disabled";

            eth2: ethernet@40066000 {
                compatible = "linkedsemi,ethernet", "snps,designware-ethernet";
                reg = <0x40066000 0x2000>;
                interrupts = <ETH2_IRQN 3>;
                clock-frequency = <PBUS0123_CLOCK>;
                clocks = <ETH2_CLOCK>;
                resets = <ETH2_RESET>;
                status = "disabled";
            };
        };

        spi1: spi@4008a000 {
            compatible = "linkedsemi,ls-spi";
            #address-cells = <1>;
            #size-cells = <0>;
            reg = <0x4008a000 0x400>;
            clock-frequency = <PBUS4_CLOCK>;
            interrupts = <SPI1_IRQN 3>;
            clocks = <SPI1_CLOCK>;
            resets = <SPI1_RESET>;
            status = "disabled";
        };

        spi2: spi@4008a400 {
            compatible = "linkedsemi,ls-spi";
            #address-cells = <1>;
            #size-cells = <0>;
            reg = <0x4008a400 0x400>;
            clock-frequency = <PBUS4_CLOCK>;
            interrupts = <SPI2_IRQN 3>;
            clocks = <SPI2_CLOCK>;
            resets = <SPI2_RESET>;
            status = "disabled";
        };

        spi3: spi@4006e000 {
            compatible = "snps,designware-spi";
            #address-cells = <1>;
            #size-cells = <0>;
            reg = <0x4006e000 0x400>;
            clock-frequency = <PBUS0123_CLOCK>;
            interrupts = <SPI3_IRQN 3>;
            clocks = <SPI3_CLOCK>;
            resets = <SPI3_RESET>;
            fifo-depth = <4>;
            max-xfer-size = <32>;
            dmas =<&dmac1 0 DMA_SPI3_RX>,<&dmac1 1 DMA_SPI3_TX>;
            dma-names ="rx","tx";
            status = "disabled";
        };

        spi4: spi@4006e400 {
            compatible = "snps,designware-spi";
            #address-cells = <1>;
            #size-cells = <0>;
            reg = <0x4006e400 0x400>;
            clock-frequency = <PBUS0123_CLOCK>;
            interrupts = <SPI4_IRQN 3>;
            clocks = <SPI4_CLOCK>;
            resets = <SPI4_RESET>;
            fifo-depth = <4>;
            max-xfer-size = <32>;
            dmas =<&dmac2 0 DMA_SPI4_RX>,<&dmac2 1 DMA_SPI4_TX>;
            dma-names ="rx","tx";
            status = "disabled";
        };

        peci1: peci@4008d800 {
            compatible = "linkedsemi,ls-peci";
            reg = <0x4008d800 0x400>;
            #address-cells= <1>;
            #size-cells = <0>;
            interrupts = <PECI1_IRQN 3>;
            clock-source = <CLK_SRC_PBUS4>;
            clocks = <PECI1_CLOCK>;
            resets = <PECI1_RESET>;
            peci-frequence = <200000>;
            status = "disabled";
        };

        peci2: peci@4008dc00 {
            compatible = "linkedsemi,ls-peci";
            reg = <0x4008dc00 0x400>;
            #address-cells= <1>;
            #size-cells = <0>;
            clock-source = <CLK_SRC_PBUS4>;
            interrupts = <PECI2_IRQN 3>;
            clocks = <PECI2_CLOCK>;
            resets = <PECI2_RESET>;
            peci-frequence = <200000>;
            status = "disabled";
        };

        sdhci1: sdhci@40049000 {
            compatible = "linkedsemi,sdhci";
            reg = <0x40049000 0x1000>;
            interrupts = <EMMC1_IRQN 3>;
            clocks = <EMMC1_CLOCK>;
            resets = <EMMC1_RESET>;
            clock-frequency = <SDHCI_CLOCK>;
#if 0
            max-bus-freq = <SDHCI_CLOCK>;
#else
            max-bus-freq = <5000000>;
#endif
            min-bus-freq = <50000>;
            status = "disabled";
        };

        sdhci2: sdhci@4004a000 {
            compatible = "linkedsemi,sdhci";
            reg = <0x4004a000 0x1000>;
            interrupts = <EMMC2_IRQN 3>;
            clocks = <EMMC2_CLOCK>;
            resets = <EMMC2_RESET>;
            clock-frequency = <SDHCI_CLOCK>;
            max-bus-freq = <SDHCI_CLOCK>;
            min-bus-freq = <50000>;
            status = "disabled";
        };

        jtag1: jtag@40092000 {
            compatible = "linkedsemi,ls-jtag";
            reg = <0x40092000 0x400>;
            interrupts = <MJTAG1_IRQN 3>;
            clocks = <MJTAG1_CLOCK>;
            resets = <MJTAG1_RESET>;
            clock-source = <CLK_SRC_PBUS4>;
            bus-frequency = <1000000>;
            status = "disabled";
        };

        jtag2: jtag@40092400 {
            compatible = "linkedsemi,ls-jtag";
            reg = <0x40092400 0x400>;
            interrupts = <MJTAG2_IRQN 3>;
            clocks = <MJTAG2_CLOCK>;
            resets = <MJTAG2_RESET>;
            clock-source = <CLK_SRC_PBUS4>;
            bus-frequency = <1000000>;
            status = "disabled";
        };

        jtag3: jtag@40092800 {
            compatible = "linkedsemi,ls-jtag";
            reg = <0x40092800 0x400>;
            interrupts = <MJTAG3_IRQN 3>;
            clocks = <MJTAG3_CLOCK>;
            resets = <MJTAG3_RESET>;
            clock-source = <CLK_SRC_PBUS4>;
            bus-frequency = <1000000>;
            status = "disabled";
        };

        i3c1: i3c@400a0800 {
            compatible = "linkedsemi,i3c";
            #address-cells = <3>;
            #size-cells = <0>;
            reg = <0x400a0800 0x2000>;
            interrupts = <I3C1_IRQN 3>;
            clocks = <I3C1_CLOCK>;
            resets = <I3C1_RESET>;
            i3c-scl-hz = <1000000>;
            clock-frequency = <PBUS4_CLOCK>;
            status = "disabled";
        };

        i3c2: i3c@40093400 {
            compatible = "linkedsemi,i3c";
            #address-cells = <3>;
            #size-cells = <0>;
            reg = <0x40093400 0x2000>;
            interrupts = <I3C2_IRQN 3>;
            clocks = <I3C2_CLOCK>;
            resets = <I3C2_RESET>;
            i3c-scl-hz = <1000000>;
            clock-frequency = <PBUS4_CLOCK>;
            status = "disabled";
        };

        i3c3: i3c@40093800 {
            compatible = "linkedsemi,i3c";
            #address-cells = <3>;
            #size-cells = <0>;
            reg = <0x40093800 0x2000>;
            interrupts = <I3C3_IRQN 3>;
            clocks = <I3C3_CLOCK>;
            resets = <I3C3_RESET>;
            i3c-scl-hz = <1000000>;
            clock-frequency = <PBUS4_CLOCK>;
            status = "disabled";
        };

        i3c4: i3c@40093c00 {
            compatible = "linkedsemi,i3c";
            #address-cells = <3>;
            #size-cells = <0>;
            reg = <0x40093c00 0x2000>;
            interrupts = <I3C4_IRQN 3>;
            clocks = <I3C4_CLOCK>;
            resets = <I3C4_RESET>;
            i3c-scl-hz = <1000000>;
            clock-frequency = <PBUS4_CLOCK>;
            status = "disabled";
        };

        i3c5: i3c@40094000 {
            compatible = "linkedsemi,i3c";
            #address-cells = <3>;
            #size-cells = <0>;
            reg = <0x40094000 0x2000>;
            interrupts = <I3C5_IRQN 3>;
            clocks = <I3C5_CLOCK>;
            resets = <I3C5_RESET>;
            i3c-scl-hz = <1000000>;
            clock-frequency = <PBUS4_CLOCK>;
            status = "disabled";
        };

        i3c6: i3c@40094400 {
            compatible = "linkedsemi,i3c";
            #address-cells = <3>;
            #size-cells = <0>;
            reg = <0x40094400 0x2000>;
            interrupts = <I3C6_IRQN 3>;
            clocks = <I3C6_CLOCK>;
            resets = <I3C6_RESET>;
            i3c-scl-hz = <1000000>;
            clock-frequency = <PBUS4_CLOCK>;
            status = "disabled";
        };

        i3c7: i3c@40094800 {
            compatible = "linkedsemi,i3c";
            #address-cells = <3>;
            #size-cells = <0>;
            reg = <0x40094800 0x2000>;
            interrupts = <I3C7_IRQN 3>;
            clocks = <I3C7_CLOCK>;
            resets = <I3C7_RESET>;
            i3c-scl-hz = <1000000>;
            clock-frequency = <PBUS4_CLOCK>;
            status = "disabled";
        };

        i3c8: i3c@40094c00 {
            compatible = "linkedsemi,i3c";
            #address-cells = <3>;
            #size-cells = <0>;
            reg = <0x40094c00 0x2000>;
            interrupts = <I3C8_IRQN 3>;
            clocks = <I3C8_CLOCK>;
            resets = <I3C8_RESET>;
            i3c-scl-hz = <1000000>;
            clock-frequency = <PBUS4_CLOCK>;
            status = "disabled";
        };

        i3c9: i3c@40095000 {
            compatible = "linkedsemi,i3c";
            #address-cells = <3>;
            #size-cells = <0>;
            reg = <0x40095000 0x2000>;
            interrupts = <I3C9_IRQN 3>;
            clocks = <I3C9_CLOCK>;
            resets = <I3C9_RESET>;
            i3c-scl-hz = <1000000>;
            clock-frequency = <PBUS4_CLOCK>;
            status = "disabled";
        };

        i3c10: i3c@40095400 {
            compatible = "linkedsemi,i3c";
            #address-cells = <3>;
            #size-cells = <0>;
            reg = <0x40095400 0x2000>;
            interrupts = <I3C10_IRQN 3>;
            clocks = <I3C10_CLOCK>;
            resets = <I3C10_RESET>;
            i3c-scl-hz = <1000000>;
            clock-frequency = <PBUS4_CLOCK>;
            status = "disabled";
        };

        i3c11: i3c@40095800 {
            compatible = "linkedsemi,i3c";
            #address-cells = <3>;
            #size-cells = <0>;
            reg = <0x40095800 0x2000>;
            interrupts = <I3C11_IRQN 3>;
            clocks = <I3C11_CLOCK>;
            resets = <I3C11_RESET>;
            i3c-scl-hz = <1000000>;
            clock-frequency = <PBUS4_CLOCK>;
            status = "disabled";
        };

        i3c12: i3c@40095c00 {
            compatible = "linkedsemi,i3c";
            #address-cells = <3>;
            #size-cells = <0>;
            reg = <0x40095c00 0x2000>;
            interrupts = <I3C12_IRQN 3>;
            clocks = <I3C12_CLOCK>;
            resets = <I3C12_RESET>;
            i3c-scl-hz = <1000000>;
            clock-frequency = <PBUS4_CLOCK>;
            status = "disabled";
        };

        i3c13: i3c@40096000 {
            compatible = "linkedsemi,i3c";
            #address-cells = <3>;
            #size-cells = <0>;
            reg = <0x40096000 0x2000>;
            interrupts = <I3C13_IRQN 3>;
            clocks = <I3C13_CLOCK>;
            resets = <I3C13_RESET>;
            i3c-scl-hz = <1000000>;
            clock-frequency = <PBUS4_CLOCK>;
            status = "disabled";
        };

        i3c14: i3c@40096400 {
            compatible = "linkedsemi,i3c";
            #address-cells = <3>;
            #size-cells = <0>;
            reg = <0x40096400 0x2000>;
            interrupts = <I3C14_IRQN 3>;
            clocks = <I3C14_CLOCK>;
            resets = <I3C14_RESET>;
            i3c-scl-hz = <1000000>;
            clock-frequency = <PBUS4_CLOCK>;
            status = "disabled";
        };

        usb2: usb@40050000 {
            compatible = "snps,dwc3";
            reg = <0x40050000 0xe000>;
            interrupts = <USB2_IRQN 3>;
            clocks = <USB2_CLOCK>;
            resets = <USB2_RESET>;
            num-in-eps = <4>;
            num-out-eps = <4>;
            status = "disabled";
        };

        usb1: usb@40043000 {
            compatible = "linkedsemi,ls-fs-usb";
            reg = <0x40043000 0x1000>;
            clocks = <USB1_CLOCK>;
            resets = <USB1_RESET>;
            interrupts = <USB1_IRQN 3>;
            num-bidir-endpoints = <8>;
            maximum-speed = "full-speed";
            ram-size = <64>;
            status = "disabled";
        };

        adc1: adc@4008b000 {
            compatible = "linkedsemi,ls-adc";
            reg = <0x4008b000 0x400>;
            interrupts = <ADC1_IRQN 3>;
            clocks = <ADC1_CLOCK>;
            clock-source = <CLK_SRC_PBUS4>;
            resets = <ADC1_RESET>;
            status = "disabled";
        };

        adc2: adc@4008b400 {
            compatible = "linkedsemi,ls-adc";
            reg = <0x4008b400 0x400>;
            interrupts = <ADC2_IRQN 3>;
            clocks = <ADC2_CLOCK>;
            clock-source = <CLK_SRC_PBUS4>;
            resets = <ADC2_RESET>;
            status = "disabled";
        };
    };

    power-states {
        idle: idle{
            compatible = "zephyr,power-state";
            power-state-name = "runtime-idle";
        };

        lp0: lp0 {
            compatible = "zephyr,power-state";
            power-state-name = "standby";
        };
    };
};

#include "lsqsh_pinctrl_fixed_pinmap.dtsi"
